# StarFive VisionFive 2 v1.2A register map
File version: 0.1
Registers are 32-bit, read-write, reset 0x0 unless marked. A register's access mark holds for its fields unless they carry their own. Offsets are from the block's base; [hi:lo] are bit positions; {n}, {i} and the like mark numbered series.

## uart0 — From snps,dw-apb-uart, peripheral generator
Base 0x10000000
Same registers: uart1 0x10010000, uart2 0x10020000, uart3 0x12000000, uart4 0x12010000, uart5 0x12020000
0x00 rbr — Receive Buffer Register
  [7:0] rbr ro — Data byte received on the serial input port (sin) in UART mode, or the serial infrared input (sir_in) in infrared mode. The data in this register is valid only if the Data Ready (DR) bit in the Line Status Register (LCR) is set. If in non-FIFO mode (FIFO_MODE == NONE) or FIFOs are disabled (FCR[0] set to zero), the data in the RBR must be read before the next data arrives, otherwise it is overwritten, resulting in an over-run error. If in FIFO mode (FIFO_MODE != NONE) and FIFOs are enabled (FCR[0] set to one), this register accesses the head of the receive FIFO. If the receive FIFO is full and this register is not read before the next data character arrives, then the data already in the FIFO is preserved, but any incoming data are lost and an over-run error occurs.
0x00 thr — Transmit Holding Register
  [7:0] thr wo — Data to be transmitted on the serial output port (sout) in UART mode or the serial infrared output (sir_out_n) in infrared mode. Data should only be written to the THR when the THR Empty (THRE) bit (LSR[5]) is set. If in non-FIFO mode or FIFOs are disabled (FCR[0] = 0) and THRE is set, writing a single character to the THR clears the THRE. Any additional writes to the THR before the THRE is set again causes the THR data to be overwritten. If in FIFO mode and FIFOs are enabled (FCR[0] = 1) and THRE is set, x number of characters of data may be written to the THR before the FIFO is full. The number x (default=16) is determined by the value of FIFO Depth that you set during configuration. Any attempt to write data when the FIFO is full results in the write data being lost.
0x00 dll — Divisor Latch Low
  [7:0] dll — Lower 8 bits of a 16-bit, read/write, Divisor Latch register that contains the baud rate divisor for the UART. This register may only be accessed when the DLAB bit (LCR[7]) is set and the UART is not busy (USR[0] is zero). The output baud rate is equal to the serial clock (pclk if one clock design, sclk if two clock design (CLOCK_MODE == Enabled)) frequency divided by sixteen times the value of the baud rate divisor, as follows: baud rate = (serial clock freq) / (16 * divisor). Note that with the Divisor Latch Registers (DLL and DLH) set to zero, the baud clock is disabled and no serial communications occur. Also, once the DLL is set, at least 8 clock cycles of the slowest DW_apb_uart clock should be allowed to pass before transmitting or receiving data.
0x04 dlh — Divisor Latch High
  [7:0] dlh — Upper 8-bits of a 16-bit, read/write, Divisor Latch register that contains the baud rate divisor for the UART. This register may only be accessed when the DLAB bit (LCR[7]) is set and the UART is not busy (USR[0] is zero). The output baud rate is equal to the serial clock (pclk if one clock design, sclk if two clock design (CLOCK_MODE == Enabled)) frequency divided by sixteen times the value of the baud rate divisor, as follows: baud rate = (serial clock freq) / (16 * divisor). Note that with the Divisor Latch Registers (DLL and DLH) set to zero, the baud clock is disabled and no serial communications occur. Also, once the DLH is set, at least 8 clock cycles of the slowest DW_apb_uart clock should be allowed to pass before transmitting or receiving data.
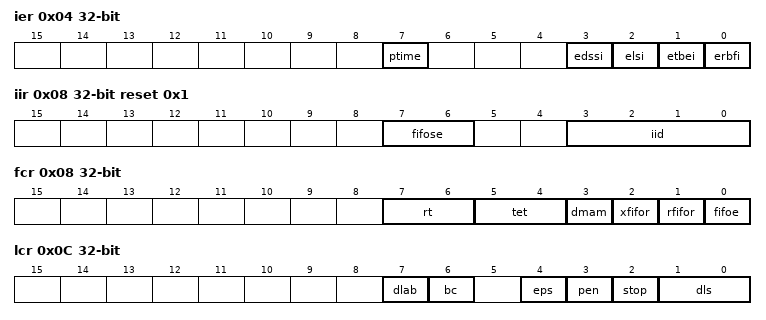
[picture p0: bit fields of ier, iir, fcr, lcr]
0x04 ier — Interrupt Enable Register
  [7] ptime — Programmable THRE Interrupt Mode Enable that can be written to only when THRE_MODE_USER == Enabled, always readable. This is used to enable/disable the generation of THRE Interrupt. 0 = disabled 1 = enabled
  [3] edssi — Enable Modem Status Interrupt. This is used to enable/disable the generation of Modem Status Interrupt. This is the fourth highest priority interrupt. 0 = disabled 1 = enabled
  [2] elsi — Enable Receiver Line Status Interrupt. This is used to enable/disable the generation of Receiver Line Status Interrupt. This is the highest priority interrupt. 0 = disabled 1 = enabled
  [1] etbei — Enable Transmit Holding Register Empty Interrupt. This is used to enable/disable the generation of Transmitter Holding Register Empty Interrupt. This is the third highest priority interrupt. 0 = disabled 1 = enabled
  [0] erbfi — Enable Received Data Available Interrupt. This is used to enable/disable the generation of Received Data Available Interrupt and the Character Timeout Interrupt (if in FIFO mode and FIFOs enabled). These are the second highest priority interrupts. 0 = disabled 1 = enabled
0x08 iir reset 0x1 — Interrupt Identity Register
  [7:6] fifose ro — FIFOs Enabled. This is used to indicate whether the FIFOs are enabled or disabled. 00 = disabled 11 = enabled
  [3:0] iid ro — Interrupt ID. This indicates the highest priority pending interrupt which can be one of the following types: 0000 = modem status 0001 = no interrupt pending 0010 = THR empty 0100 = received data available 0110 = receiver line status 0111 = busy detect 1100 = character timeout The interrupt priorities are split into four levels that are detailed in Table 8 on page 97. Bit 3 indicates an interrupt can only occur when the FIFOs are enabled and used to distinguish a Character Timeout condition interrupt.
0x08 fcr — FIFO Control Register
  [7:6] rt wo — RCVR Trigger. This is used to select the trigger level in the receiver FIFO at which the Received Data Available Interrupt is generated. In auto flow control mode it is used to determine when the rts_n signal is de-asserted. It also determines when the dma_rx_req_n signal is asserted in certain modes of operation. For details on DMA support, refer to “DMA Support” on page 58. The following trigger levels are supported: 00 = 1 character in the FIFO 01 = FIFO ¼ full 10 = FIFO ½ full 11 = FIFO 2 less than full
  [5:4] tet wo — TX Empty Trigger. Writes have no effect when THRE_MODE_USER == Disabled. This is used to select the empty threshold level at which the THRE Interrupts are generated when the mode is active. It also determines when the dma_tx_req_n signal is asserted when in certain modes of operation. For details on DMA support, refer to “DMA Support” on page 58. The following trigger levels are supported: 00 = FIFO empty 01 = 2 characters in the FIFO 10 = FIFO ¼ full 11 = FIFO ½ full
  [3] dmam wo — DMA Mode. This determines the DMA signalling mode used for the dma_tx_req_n and dma_rx_req_n output signals when additional DMA handshaking signals are not selected (DMA_EXTRA == No). For details on DMA support, refer to “DMA Support” on page 58. 0 = mode 0 1 = mode 1
  [2] xfifor wo — XMIT FIFO Reset. This resets the control portion of the transmit FIFO and treats the FIFO as empty. This also de-asserts the DMA TX request and single signals when additional DMA handshaking signals are selected (DMA_EXTRA == YES). Note that this bit is 'self-clearing'. It is not necessary to clear this bit.
  [1] rfifor wo — RCVR FIFO Reset. This resets the control portion of the receive FIFO and treats the FIFO as empty. This also de-asserts the DMA RX request and single signals when additional DMA handshaking signals are selected (DMA_EXTRA == YES). Note that this bit is 'self-clearing'. It is not necessary to clear this bit.
  [0] fifoe wo — FIFO Enable. This enables/disables the transmit (XMIT) and receive (RCVR) FIFOs. Whenever the value of this bit is changed both the XMIT and RCVR controller portion of FIFOs is reset.
0x0C lcr — Line Control Register
  [7] dlab — Divisor Latch Access Bit. Writeable only when UART is not busy (USR[0] is zero), always readable. This bit is used to enable reading and writing of the Divisor Latch register (DLL and DLH) to set the baud rate of the UART. This bit must be cleared after initial baud rate setup in order to access other registers.
  [6] bc — Break Control Bit.This is used to cause a break condition to be transmitted to the receiving device. If set to one the serial output is forced to the spacing (logic 0) state. When not in Loopback Mode, as determined by MCR[4], the sout line is forced low until the Break bit is cleared. If SIR_MODE == Enabled and active (MCR[6] set to one) the sir_out_n line is continuously pulsed. When in Loopback Mode, the break condition is internally looped back to the receiver and the sir_out_n line is forced low.
  [4] eps — Even Parity Select. Writeable only when UART is not busy (USR[0] is zero), always readable. This is used to select between even and odd parity, when parity is enabled (PEN set to one). If set to one, an even number of logic 1s is transmitted or checked. If set to zero, an odd number of logic 1s is transmitted or checked.
  [3] pen — Parity Enable. Writeable only when UART is not busy (USR[0] is zero), always readable. This bit is used to enable and disable parity generation and detection in transmitted and received serial character respectively. 0 = parity disabled 1 = parity enabled
  [2] stop — Number of stop bits. Writeable only when UART is not busy (USR[0] is zero), always readable. This is used to select the number of stop bits per character that the peripheral transmits and receives. If set to zero, one stop bit is transmitted in the serial data. If set to one and the data bits are set to 5 (LCR[1:0] set to zero) one and a half stop bits is transmitted. Otherwise, two stop bits are transmitted. Note that regardless of the number of stop bits selected, the receiver checks only the first stop bit. 0 = 1 stop bit 1 = 1.5 stop bits when DLS (LCR[1:0]) is zero, else 2 stop bit
  [1:0] dls — Data Length Select. Writeable only when UART is not busy (USR[0] is zero), always readable. This is used to select the number of data bits per character that the peripheral transmits and receives. The number of bit that may be selected areas follows: 00 = 5 bits 01 = 6 bits 10 = 7 bits 11 = 8 bits
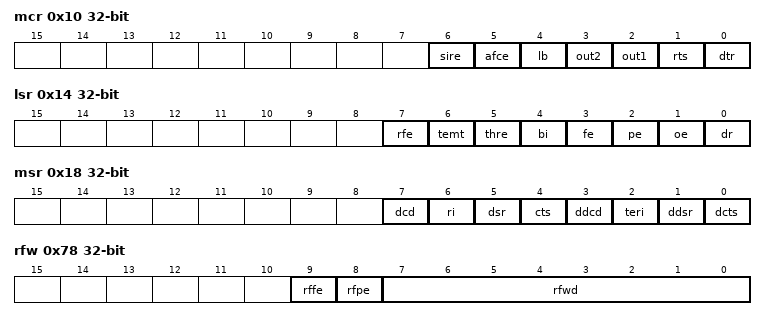
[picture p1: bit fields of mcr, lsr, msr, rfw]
0x10 mcr — Modem Control Register
  [6] sire — SIR Mode Enable. Writeable only when SIR_MODE == Enabled, always readable. This is used to enable/disable the IrDA SIR Mode features as described in “IrDA 1.0 SIR Protocol” on page 47. 0 = IrDA SIR Mode disabled 1 = IrDA SIR Mode enabled
  [5] afce — Auto Flow Control Enable. Writeable only when AFCE_MODE == Enabled, always readable. When FIFOs are enabled and the Auto Flow Control Enable (AFCE) bit is set, Auto Flow Control features are enabled as described in “Auto Flow Control” on page 51. 0 = Auto Flow Control Mode disabled 1 = Auto Flow Control Mode enabled
  [4] lb — LoopBack Bit. This is used to put the UART into a diagnostic mode for test purposes. If operating in UART mode (SIR_MODE != Enabled or not active, MCR[6] set to zero), data on the sout line is held high, while serial data output is looped back to the sin line, internally. In this mode all the interrupts are fully functional. Also, in loopback mode, the modem control inputs (dsr_n, cts_n, ri_n, dcd_n) are disconnected and the modem control outputs (dtr_n, rts_n, out1_n, out2_n) are looped back to the inputs, internally. If operating in infrared mode (SIR_MODE == Enabled AND active, MCR[6] set to one), data on the sir_out_n line is held low, while serial data output is inverted and looped back to the sir_in line
  [3] out2 — OUT2. This is used to directly control the user-designated Output2 (out2_n) output. The value written to this location is inverted and driven out on out2_n, that is: 0 = out2_n de-asserted (logic 1) 1 = out2_n asserted (logic 0) Note that in Loopback mode (MCR[4] set to one), the out2_n output is held inactive high while the value of this location is internally looped back to an input.
  [2] out1 — OUT1. This is used to directly control the user-designated Output1 (out1_n) output. The value written to this location is inverted and driven out on out1_n, that is: 0 = out1_n de-asserted (logic 1) 1 = out1_n asserted (logic 0) Note that in Loopback mode (MCR[4] set to one), the out1_n output is held inactive high while the value of this location is internally looped back to an input.
  [1] rts — Request to Send. This is used to directly control the Request to Send (rts_n) output. The Request To Send (rts_n) output is used to inform the modem or data set that the UART is ready to exchange data. When Auto RTS Flow Control is not enabled (MCR[5] set to zero), the rts_n signal is set low by programming MCR[1] (RTS) to a high.In Auto Flow Control, AFCE_MODE == Enabled and active (MCR[5] set to one) and FIFOs enable (FCR[0] set to one), the rts_n output is controlled in the same way, but is also gated with the receiver FIFO threshold trigger (rts_n is inactive high when above the threshold). The rts_n signal is de-asserted when MCR[1] is set low. Note that in Loopback mode (MCR[4] set to one), the rts_n output is held inactive high while the value of this location is internally looped back to an input.
  [0] dtr — Data Terminal Ready. This is used to directly control the Data Terminal Ready (dtr_n) output. The value written to this location is inverted and driven out on dtr_n, that is: 0 = dtr_n de-asserted (logic 1) 1 = dtr_n asserted (logic 0) The Data Terminal Ready output is used to inform the modem or data set that the UART is ready to establish communications. Note that in Loopback mode (MCR[4] set to one), the dtr_n output is held inactive high while the value of this location is internally looped back to an input.
0x14 lsr — Line Status Register
  [7] rfe ro — Receiver FIFO Error bit. This bit is only relevant when FIFO_MODE != NONE AND FIFOs are enabled (FCR[0] set to one). This is used to indicate if there is at least one parity error, framing error, or break indication in the FIFO. 0 = no error in RX FIFO 1 = error in RX FIFO This bit is cleared when the LSR is read and the character with the error is at the top of the receiver FIFO and there are no subsequent errors in the FIFO.
  [6] temt ro — Transmitter Empty bit. If in FIFO mode (FIFO_MODE != NONE) and FIFOs enabled (FCR[0] set to one), this bit is set whenever the Transmitter Shift Register and the FIFO are both empty. If in non-FIFO mode or FIFOs are disabled, this bit is set whenever the Transmitter Holding Register and the Transmitter Shift Register are both empty.
  [5] thre ro — Transmit Holding Register Empty bit. If THRE_MODE_USER == Disabled or THRE mode is disabled (IER[7] set to zero) and regardless of FIFO's being implemented/enabled or not, this bit indicates that the THR or TX FIFO is empty. This bit is set whenever data is transferred from the THR or TX FIFO to the transmitter shift register and no new data has been written to the THR or TX FIFO. This also causes a THRE Interrupt to occur, if the THRE Interrupt is enabled. If THRE_MODE_USER == Enabled AND FIFO_MODE != NONE and both modes are active (IER[7] set to one and FCR[0] set to one respectively), the functionality is switched to indicate the transmitter FIFO is full, and no longer controls THRE interrupts, which are then controlled by the FCR[5:4] threshold setting. For more details, see “Programmable THRE Interrupt” on page 54.
  [4] bi ro — Break Interrupt bit. This is used to indicate the detection of a break sequence on the serial input data. If in UART mode (SIR_MODE == Disabled), it is set whenever the serial input, sin, is held in a logic '0' state for longer than the sum of start time + data bits + parity + stop bits. If in infrared mode (SIR_MODE == Enabled), it is set whenever the serial input, sir_in, is continuously pulsed to logic '0' for longer than the sum of start time + data bits + parity + stop bits. A break condition on serial input causes one and only one character, consisting of all zeros, to be received by the UART. In the FIFO mode, the character associated with the break condition is carried through the FIFO and is revealed when the character is at the top of the FIFO. Reading the LSR clears the BI bit. In the non-FIFO mode, the BI indication occurs immediately and persists until the LSR is read.
  [3] fe ro — Framing Error bit. This is used to indicate the occurrence of a framing error in the receiver. A framing error occurs when the receiver does not detect a valid STOP bit in the received data. In the FIFO mode, since the framing error is associated with a character received, it is revealed when the character with the framing error is at the top of the FIFO. When a framing error occurs, the UART tries to resynchronize. It does this by assuming that the error was due to the start bit of the next character and then continues receiving the other bit i.e. data, and/or parity and stop. It should be noted that the Framing Error (FE) bit (LSR[3]) is set if a break interrupt has occurred, as indicated by Break Interrupt (BI) bit (LSR[4]). 0 = no framing error 1 = framing error Reading the LSR clears the FE bit.
  [2] pe ro — Parity Error bit. This is used to indicate the occurrence of a parity error in the receiver if the Parity Enable (PEN) bit (LCR[3]) is set. In the FIFO mode, since the parity error is associated with a character received, it is revealed when the character with the parity error arrives at the top of the FIFO. It should be noted that the Parity Error (PE) bit (LSR[2]) is set if a break interrupt has occurred, as indicated by Break Interrupt (BI) bit (LSR[4]). 0 = no parity error 1 = parity error Reading the LSR clears the PE bit.
  [1] oe ro — Overrun error bit. This is used to indicate the occurrence of an overrun error. This occurs if a new data character was received before the previous data was read. In the non-FIFO mode, the OE bit is set when a new character arrives in the receiver before the previous character was read from the RBR. When this happens, the data in the RBR is overwritten. In the FIFO mode, an overrun error occurs when the FIFO is full and a new character arrives at the receiver. The data in the FIFO is retained and the data in the receive shift register is lost. 0 = no overrun error 1 = overrun error Reading the LSR clears the OE bit.
  [0] dr ro — Data Ready bit. This is used to indicate that the receiver contains at least one character in the RBR or the receiver FIFO. 0 = no data ready 1 = data ready This bit is cleared when the RBR is read in non-FIFO mode, or when the receiver FIFO is empty, in FIFO mode.
0x18 msr — Line Status Register
  [7] dcd ro — Data Carrier Detect. This is used to indicate the current state of the modem control line dcd_n. This bit is the complement of dcd_n. When the Data Carrier Detect input (dcd_n) is asserted it is an indication that the carrier has been detected by the modem or data set. 0 = dcd_n input is de-asserted (logic 1) 1 = dcd_n input is asserted (logic 0) In Loopback Mode (MCR[4] set to one), DCD is the same as MCR[3] (Out2).
  [6] ri ro — Ring Indicator. This is used to indicate the current state of the modem control line ri_n. This bit is the complement of ri_n. When the Ring Indicator input (ri_n) is asserted it is an indication that a telephone ringing signal has been received by the modem or data set. 0 = ri_n input is de-asserted (logic 1) 1 = ri_n input is asserted (logic 0) In Loopback Mode (MCR[4] set to one), RI is the same as MCR[2] (Out1).
  [5] dsr ro — Data Set Ready. This is used to indicate the current state of the modem control line dsr_n. This bit is the complement of dsr_n. When the Data Set Ready input (dsr_n) is asserted it is an indication that the modem or data set is ready to establish communications with the DW_apb_uart. 0 = dsr_n input is de-asserted (logic 1) 1 = dsr_n input is asserted (logic 0) In Loopback Mode (MCR[4] set to one), DSR is the same as MCR[0] (DTR).
  [4] cts ro — Clear to Send. This is used to indicate the current state of the modem control line cts_n. This bit is the complement of cts_n. When the Clear to Send input (cts_n) is asserted it is an indication that the modem or data set is ready to exchange data with the DW_apb_uart. 0 = cts_n input is de-asserted (logic 1) 1 = cts_n input is asserted (logic 0) In Loopback Mode (MCR[4] = 1), CTS is the same as MCR[1] (RTS)
  [3] ddcd ro — Delta Data Carrier Detect. This is used to indicate that the modem control line dcd_n has changed since the last time the MSR was read. 0 = no change on dcd_n since last read of MSR 1 = change on dcd_n since last read of MSR Reading the MSR clears the DDCD bit. In Loopback Mode (MCR[4] = 1), DDCD reflects changes on MCR[3] (Out2). Note, if the DDCD bit is not set and the dcd_n signal is asserted (low) and a reset occurs (software or otherwise), then the DDCD bit is set when the reset is removed if the dcd_n signal remains asserted.
  [2] teri ro — Trailing Edge of Ring Indicator. This is used to indicate that a change on the input ri_n (from an active-low to an inactive-high state) has occurred since the last time the MSR was read. 0 = no change on ri_n since last read of MSR 1 = change on ri_n since last read of MSR Reading the MSR clears the TERI bit. In Loopback Mode (MCR[4] = 1), TERI reflects when MCR[2] (Out1) has changed state from a high to a low.
  [1] ddsr ro — Delta Data Set Ready. This is used to indicate that the modem control line dsr_n has changed since the last time the MSR was read. 0 = no change on dsr_n since last read of MSR 1 = change on dsr_n since last read of MSR Reading the MSR clears the DDSR bit. In Loopback Mode (MCR[4] = 1), DDSR reflects changes on MCR[0] (DTR). Note, if the DDSR bit is not set and the dsr_n signal is asserted (low) and a reset occurs (software or otherwise), then the DDSR bit is set when the reset is removed if the dsr_n signal remains asserted.
  [0] dcts ro — Delta Clear to Send. This is used to indicate that the modem control line cts_n has changed since the last time the MSR was read. 0 = no change on ctsdsr_n since last read of MSR 1 = change on ctsdsr_n since last read of MSR Reading the MSR clears the DCTS bit. In Loopback Mode (MCR[4] = 1), DCTS reflects changes on MCR[1] (RTS). Note, if the DCTS bit is not set and the cts_n signal is asserted (low) and a reset occurs (software or otherwise), then the DCTS bit is set when the reset is removed if the cts_n signal remains asserted.
0x1C scr — Scratch Pad Register
  [7:0] scr — This register is for programmers to use as a temporary storage space. It has no defined purpose in the DW_apb_uart.
0x20 lpdll — Low Power Divisor Latch Low Register: This register is only valid when the DW_apb_uart is configured to have SIR low-power reception capabilities implemented (SIR_LP_RX = Yes). If SIR low-power reception capabilities are not implemented, this register does not exist and reading from thsi register address returns zero.
  [7:0] lpdll — This register makes up the lower 8-bits of a 16-bit, read/write, Low Power Divisor Latch register that contains the baud rate divisor for the UART, which must give a baud rate of 115.2K. This is required for SIR Low Power (minimum pulse width) detection at the receiver. This register may only be accessed when the DLAB bit (LCR[7]) is set and the UART is not busy (USR[0]) is 0). The output low-power baud rate is equal to the serial clock (sclk) frequency divided by sixteen times the value of the baud rate divisor, as follows: Low power baud rate = (serial clock frequency)/(16* divisor) Therefore, a divisor must be selected to give a baud rate of 115.2K. NOTE: When the Low Power Divisor Latch registers (LPDLL and LPDLH) are set to 0, the low-power baud clock is disabled and no low-power pulse detection (or any pulse detection) occurs at the receiver. Also, once the LPDLL is set, at least eight clock cycles of the slowest DW_apb_uart clock should be allowed to pass before transmitting or receiving data.
0x24 lpdlh — Low Power Divisor Latch High Register: This register is only valid when the DW_apb_uart is configured to have SIR low-power reception capabilities implemented (SIR_LP_RX = Yes). If SIR low-power reception capabilities are not implemented, this register does not exist and reading from thsi register address returns zero.
  [7:0] lpdlh — This register makes up the upper 8-bits of a 16-bit, read/write, Low Power Divisor Latch register that contains the baud rate divisor for the UART, which must give a baud rate of 115.2K. This is required for SIR Low Power (minimum pulse width) detection at the receiver. This register may only be accessed when the DLAB bit (LCR[7]) is set and the UART is not busy (USR[0]) is 0). The output low-power baud rate is equal to the serial clock (sclk) frequency divided by sixteen times the value of the baud rate divisor, as follows: Low power baud rate = (serial clock frequency)/(16* divisor) Therefore, a divisor must be selected to give a baud rate of 115.2K. NOTE: When the Low Power Divisor Latch registers (LPDLL and LPDLH) are set to 0, the low-power baud clock is disabled and no low-power pulse detection (or any pulse detection) occurs at the receiver. Also, once the LPDLH is set, at least eight clock cycles of the slowest DW_apb_uart clock should be allowed to pass before transmitting or receiving data
{0x30+4i} srbr{i} (i=0..15) — Shadow Receive Buffer Register {i}: This register is only valid when the DW_apb_uart is configured to have additional shadow registers implemented (SHADOW == YES). If shadow registers are not implemented, this register does not exist and reading from this register address returns zero.
  [7:0] srbr ro — This is a shadow register for the RBR and has been allocated sixteen 32-bit locations so as to accommodate burst accesses from the master. This register contains the data byte received on the serial input port (sin) in UART mode or the serial infrared input (sir_in) in infrared mode. The data in this register is valid only if the Data Ready (DR) bit in the Line status Register (LSR) is set. If in non-FIFO mode (FIFO_MODE == NONE) or FIFOs are disabled (FCR[0] set to zero), the data in the RBR must be read before the next data arrives, otherwise it is overwritten, resulting in an overrun error. If in FIFO mode (FIFO_MODE != NONE) and FIFOs are enabled (FCR[0] set to one), this register accesses the head of the receive FIFO. If the receive FIFO is full and this register is not read before the next data character arrives, then the data already in the FIFO are preserved, but any incoming data is lost. An overrun error also occurs.
{0x30+4i} sthr{i} (i=0..15) — Shadow Transmit Holding Register {i}: This register is only valid when the DW_apb_uart is configured to have additional shadow registers implemented (SHADOW == YES). If shadow registers are not implemented, this register does not exist and reading from this register address returns zero.
  [7:0] sthr wo — This is a shadow register for the THR and has been allocated sixteen 32-bit locations so as to accommodate burst accesses from the master. This register contains data to be transmitted on the serial output port (sout) in UART mode or the serial infrared output (sir_out_n) in infrared mode. Data should only be written to the THR when the THR Empty (THRE) bit (LSR[5]) is set. If in non-FIFO mode or FIFOs are disabled (FCR[0] set to zero) and THRE is set, writing a single character to the THR clears the THRE. Any additional writes to the THR before the THRE is set again causes the THR data to be overwritten. If in FIFO mode and FIFOs are enabled (FCR[0] set to one) and THRE is set, x number of characters of data may be written to the THR before the FIFO is full. The number x (default=16) is determined by the value of FIFO Depth that you set during configuration. Any attempt to write data when the FIFO is full results in the write data being lost.
0x70 far — FIFO Access Register
  [0] far — Writes have no effect when FIFO_ACCESS == No, always readable. This register is use to enable a FIFO access mode for testing, so that the receive FIFO can be written by the master and the transmit FIFO can be read by the master when FIFOs are implemented and enabled. When FIFOs are not implemented or not enabled it allows the RBR to be written by the master and the THR to be read by the master. 0 = FIFO access mode disabled 1 = FIFO access mode enabled Note, that when the FIFO access mode is enabled/disabled, the control portion of the receive FIFO and transmit FIFO is reset and the FIFOs are treated as empty.
0x74 tfr — Transmit FIFO Read
  [7:0] tfr ro — Transmit FIFO Read. These bits are only valid when FIFO access mode is enabled (FAR[0] is set to one). When FIFOs are implemented and enabled, reading this register gives the data at the top of the transmit FIFO. Each consecutive read pops the transmit FIFO and gives the next data value that is currently at the top of the FIFO. When FIFOs are not implemented or not enabled, reading this register gives the data in the THR.
0x78 rfw — Receive FIFO Write
  [9] rffe wo — Receive FIFO Framing Error. These bits are only valid when FIFO access mode is enabled (FAR[0] is set to one). When FIFOs are implemented and enabled, this bit is used to write framing error detection information to the receive FIFO. When FIFOs are not implemented or not enabled, this bit is used to write framing error detection information to the RBR.
  [8] rfpe wo — Receive FIFO Parity Error. These bits are only valid when FIFO access mode is enabled (FAR[0] is set to one). When FIFOs are implemented and enabled, this bit is used to write parity error detection information to the receive FIFO. When FIFOs are not implemented or not enabled, this bit is used to write parity error detection information to the RBR.
  [7:0] rfwd wo — Receive FIFO Write Data. These bits are only valid when FIFO access mode is enabled (FAR[0] is set to one). When FIFOs are implemented and enabled, the data that is written to the RFWD is pushed into the receive FIFO. Each consecutive write pushes the new data to the next write location in the receive FIFO. When FIFOs are not implemented or not enabled, the data that is written to the RFWD is pushed into the RBR.
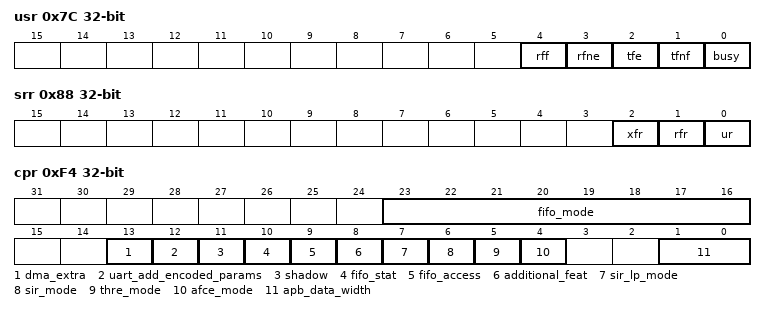
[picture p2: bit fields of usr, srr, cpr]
0x7C usr — UART Status Register
  [4] rff ro — Receive FIFO Full. This bit is only valid when FIFO_STAT == YES. This is used to indicate that the receive FIFO is completely full. 0 = Receive FIFO not full 1 = Receive FIFO Full This bit is cleared when the RX FIFO is no longer full.
  [3] rfne ro — Receive FIFO Not Empty. This bit is only valid when FIFO_STAT == YES. This is used to indicate that the receive FIFO contains one or more entries. 0 = Receive FIFO is empty 1 = Receive FIFO is not empty This bit is cleared when the RX FIFO is empty.
  [2] tfe ro — Transmit FIFO Empty. This bit is only valid when FIFO_STAT == YES. This is used to indicate that the transmit FIFO is completely empty. 0 = Transmit FIFO is not empty 1 = Transmit FIFO is empty This bit is cleared when the TX FIFO is no longer empty.
  [1] tfnf ro — Transmit FIFO Not Full. This bit is only valid when FIFO_STAT == YES. This is used to indicate that the transmit FIFO in not full. 0 = Transmit FIFO is full 1 = Transmit FIFO is not full This bit is cleared when the TX FIFO is full.
  [0] busy ro — UART Busy. This is indicates that a serial transfer is in progress, when cleared indicates that the DW_apb_uart is idle or inactive. 0 = DW_apb_uart is idle or inactive 1 = DW_apb_uart is busy (actively transferring data) NOTE: It is possible for the UART Busy bit to be cleared even though a new character may have been sent from another device. That is, if the DW_apb_uart has no data in THR and RBR and there is no transmission in progress and a start bit of a new character has just reached the DW_apb_uart. This is due to the fact that a valid start is not seen until the middle of the bit period and this duration is dependent on the baud divisor that has been programmed. If a second system clock has been implemented (CLOCK_MODE == Enabled), the assertion of this bit is also delayed by several cycles of the slower clock.
0x80 tfl — Transmit FIFO Level: This register is only valid when the DW_apb_uart is configured to have additional FIFO status registers implemented (FIFO_STAT == YES). If status registers are not implemented, this register does not exist and reading from this register address returns zero.
  [31:0] tfl ro — Transmit FIFO Level. This is indicates the number of data entries in the transmit FIFO.
0x84 rfl — Receive FIFO Level: This register is only valid when the DW_apb_uart is configured to have additional FIFO status registers implemented (FIFO_STAT == YES). If status registers are not implemented, this register does not exist and reading from this register address returns zero.
  [31:0] rfl ro — Receive FIFO Level. This is indicates the number of data entries in the receive FIFO.
0x88 srr — Software Reset Register: This register is only valid when the DW_apb_uart is configured to have additional shadow registers implemented (SHADOW == YES). If shadow registers are not implemented, this register does not exist and reading from this register address returns zero.
  [2] xfr wo — XMIT FIFO Reset. This is a shadow register for the XMIT FIFO Reset bit (FCR[2]). This can be used to remove the burden on software having to store previously written FCR values (which are pretty static) just to reset the transmit FIFO. This resets the control portion of the transmit FIFO and treats the FIFO as empty. This also de-asserts the DMA TX request and single signals when additional DMA handshaking signals are selected (DMA_EXTRA == YES). Note that this bit is 'self-clearing'. It is not necessary to clear this bit.
  [1] rfr wo — RCVR FIFO Reset. This is a shadow register for the RCVR FIFO Reset bit (FCR[1]). This can be used to remove the burden on software having to store previously written FCR values (which are pretty static) just to reset the receive FIFO This resets the control portion of the receive FIFO and treats the FIFO as empty. This also de-asserts the DMA RX request and single signals when additional DMA handshaking signals are selected (DMA_EXTRA == YES). Note that this bit is 'self-clearing'. It is not necessary to clear this bit.
  [0] ur wo — UART Reset. This asynchronously resets the DW_apb_uart and synchronously removes the reset assertion. For a two clock implementation both pclk and sclk domains are reset.
0x8C srts — Shadow Request to Send: This register is only valid when the DW_apb_uart is configured to have additional shadow registers implemented (SHADOW == YES). If shadow registers are not implemented, this register does not exist and reading from this register address returns zero.
  [0] srts — Shadow Request to Send. This is a shadow register for the RTS bit (MCR[1]), this can be used to remove the burden of having to performing a read-modify-write on the MCR. This is used to directly control the Request to Send (rts_n) output. The Request To Send (rts_n) output is used to inform the modem or data set that the DW_apb_uart is ready to exchange data. When Auto RTS Flow Control is not enabled (MCR[5] = 0), the rts_n signal is set low by programming MCR[1] (RTS) to a high. In Auto Flow Control, AFCE_MODE == Enabled and active (MCR[5] = 1) and FIFOs enable (FCR[0] = 1), the rts_n output is controlled in the same way, but is also gated with the receiver FIFO threshold trigger (rts_n is inactive high when above the threshold). Note that in Loopback mode (MCR[4] = 1), the rts_n output is held inactive-high while the value of this location is internally looped back to an input.
0x90 sbcr — Shadow Break Control Register: This register is only valid when the DW_apb_uart is configured to have additional shadow registers implemented (SHADOW == YES). If shadow registers are not implemented, this register does not exist and reading from this register address returns zero.
  [0] sbcr — Shadow Break Control Bit. This is a shadow register for the Break bit (LCR[6]), this can be used to remove the burden of having to performing a read modify write on the LCR. This is used to cause a break condition to be transmitted to the receiving device. If set to one the serial output is forced to the spacing (logic 0) state. When not in Loopback Mode, as determined by MCR[4], the sout line is forced low until the Break bit is cleared. If SIR_MODE == Enabled and active (MCR[6] = 1) the sir_out_n line is continuously pulsed. When in Loopback Mode, the break condition is internally looped back to the receiver.
0x94 sdmam — Shadow DMA Mode: This register is only valid when the DW_apb_uart is configured to have additional FIFO registers implemented (FIFO_MODE != None) and additional shadow registers implemented (SHADOW == YES). If these registers are not implemented, this register does not exist and reading from this register address returns zero.
  [0] sdmam — Shadow DMA Mode. This is a shadow register for the DMA mode bit (FCR[3]). This can be used to remove the burden of having to store the previously written value to the FCR in memory and having to mask this value so that only the DMA Mode bit gets updated. This determines the DMA signalling mode used for the dma_tx_req_n and dma_rx_req_n output signals when additional DMA handshaking signals are not selected (DMA_EXTRA == NO). 0 = mode 0 1 = mode 1
0x98 sfe — Shadow FIFO Enable: This register is only valid when the DW_apb_uart is configured to have additional FIFO registers implemented (FIFO_MODE != None) and additional shadow registers implemented (SHADOW == YES). If these registers are not implemented, this register does not exist and reading from this register address returns zero.
  [0] sfe — Shadow FIFO Enable. This is a shadow register for the FIFO enable bit (FCR[0]). This can be used to remove the burden of having to store the previously written value to the FCR in memory and having to mask this value so that only the FIFO enable bit gets updated.This enables/disables the transmit (XMIT) and receive (RCVR) FIFOs. If this bit is set to zero (disabled) after being enabled then both the XMIT and RCVR controller portion of FIFOs are reset.
0x9C srt — Shadow RCVR Trigger: This register is only valid when the DW_apb_uart is configured to have additional FIFO registers implemented (FIFO_MODE != None) and additional shadow registers implemented (SHADOW == YES). If these registers are not implemented, this register does not exist and reading from this register address returns zero.
  [1:0] srt — Shadow RCVR Trigger. This is a shadow register for the RCVR trigger bits (FCR[7:6]). This can be used to remove the burden of having to store the previously written value to the FCR in memory and having to mask this value so that only the RCVR trigger bit gets updated. This is used to select the trigger level in the receiver FIFO at which the Received Data Available Interrupt is generated. It also determines when the dma_rx_req_n signal is asserted when DMA Mode (FCR[3]) = 1. The following trigger levels are supported: 00 = 1 character in the FIFO 01 = FIFO ¼ full 10 = FIFO ½ full 11 = FIFO 2 less than full
0xA0 stet — Shadow TX Empty Trigger: This register is only valid when the DW_apb_uart is configured to have FIFOs implemented (FIFO_MODE != NONE) and THRE interrupt support implemented (THRE_MODE_USER == Enabled) and additional shadow registers implemented (SHADOW == YES). If FIFOs are not implemented or THRE interrupt support is not implemented or shadow registers are not implemented, this register does not exist and reading from this register address returns zero.
  [1:0] stet — Shadow TX Empty Trigger. This is a shadow register for the TX empty trigger bits (FCR[5:4]). This can be used to remove the burden of having to store the previously written value to the FCR in memory and having to mask this value so that only the TX empty trigger bit gets updated. This is used to select the empty threshold level at which the THRE Interrupts are generated when the mode is active. The following trigger levels are supported: 00 = FIFO empty 01 = 2 characters in the FIFO 10 = FIFO ¼ full 11 = FIFO ½ full
0xA4 htx — Halt TX
  [0] htx — This register is use to halt transmissions for testing, so that the transmit FIFO can be filled by the master when FIFOs are implemented and enabled. 0 = Halt TX disabled 1 = Halt TX enabled Note, if FIFOs are implemented and not enabled, the setting of the halt TX register has no effect on operation.
0xA8 dmasa — DMA Software Acknowledge
  [0] dmasa wo — This register is use to perform a DMA software acknowledge if a transfer needs to be terminated due to an error condition. For example, if the DMA disables the channel, then the DW_apb_uart should clear its request. This causes the TX request, TX single, RX request and RX single signals to de-assert. Note that this bit is 'self-clearing'. It is not necessary to clear this bit.
0xF4 cpr — Component Parameter Register: This register is only valid when the DW_apb_uart is configured to have the Component Parameter register implemented (UART_ADD_ENCODED_PARAMS == YES). If the Component Parameter register is not implemented, this register does not exist and reading from this register address returns zero.
  [23:16] fifo_mode ro — 0x00 = 0 0x01 = 16 0x02 = 32 to 0x80 = 2048 0x81 - 0xff = reserved
  [13] dma_extra ro — 0 = false 1 = true
  [12] uart_add_encoded_params ro — 0 = false 1 = true
  [11] shadow ro — 0 = false 1 = true
  [10] fifo_stat ro — 0 = false 1 = true
  [9] fifo_access ro — 0 = false 1 = true
  [8] additional_feat ro — 0 = false 1 = true
  [7] sir_lp_mode ro — 0 = false 1 = true
  [6] sir_mode ro — 0 = false 1 = true
  [5] thre_mode ro — 0 = false 1 = true
  [4] afce_mode ro — 0 = false 1 = true
  [1:0] apb_data_width ro — 00 = 8 bits 01 = 16 bits 10 = 32 bits 11 = reserved
0xF8 ucv — UART Component Version: This register is only valid when the DW_apb_uart is configured to have additional features implemented (ADDITIONAL_FEATURES == YES). If additional features are not implemented, this register does not exist and reading from this register address returns zero.
  [31:0] ucv ro — ASCII value for each number in the version, followed by *. For example 32_30_31_2A represents the version 2.01*
0xF8 ctr reset 0x44570110 — Component Type Register: This register is only valid when the DW_apb_uart is configured to have additional features implemented (ADDITIONAL_FEATURES == YES). If additional features are not implemented, this register does not exist and reading from this register address returns zero.
  [31:0] ctr ro — This register contains the peripherals identification code.
